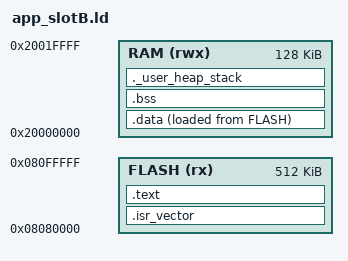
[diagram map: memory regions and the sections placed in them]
/* Concrete Slot B linker script -- used by ci/Makefile.app when SLOT=B.
 * Identical to app_slotA.ld except for FLASH ORIGIN/LENGTH below. See
 * DESIGN.md for why the app is built twice rather than as one
 * position-independent binary. */

ENTRY(Reset_Handler)

MEMORY
{
  FLASH (rx)  : ORIGIN = 0x08080000, LENGTH = 512K
  RAM   (rwx) : ORIGIN = 0x20000000, LENGTH = 128K
}

_estack = ORIGIN(RAM) + LENGTH(RAM);

SECTIONS
{
  .isr_vector :
  {
    . = ALIGN(4);
    KEEP(*(.isr_vector))
    . = ALIGN(4);
  } > FLASH

  .text :
  {
    . = ALIGN(4);
    *(.text)
    *(.text*)
    *(.rodata)
    *(.rodata*)
    . = ALIGN(4);
    _etext = .;
  } > FLASH

  .data :
  {
    . = ALIGN(4);
    _sdata = .;
    *(.data)
    *(.data*)
    . = ALIGN(4);
    _edata = .;
  } > RAM AT> FLASH
  _sidata = LOADADDR(.data);

  .bss :
  {
    . = ALIGN(4);
    _sbss = .;
    *(.bss)
    *(.bss*)
    *(COMMON)
    . = ALIGN(4);
    _ebss = .;
  } > RAM

  ._user_heap_stack :
  {
    . = ALIGN(8);
    PROVIDE ( end = . );
    . = . + 0x2000;
    . = ALIGN(8);
  } > RAM
}
